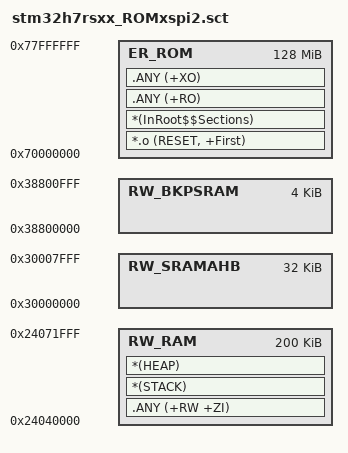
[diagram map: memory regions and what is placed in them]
; *************************************************************
; *** Scatter-Loading Description File generated by uVision ***
; *************************************************************

LOAD_FLASH 0x70000000 0x10000000  {    ; load region size_region
  ER_ROM 0x70000000 0x08000000  {  ; load address = execution address
   *.o (RESET, +First)
   *(InRoot$$Sections)
   .ANY (+RO)
   .ANY (+XO)
  }

  RW_SRAMAHB 0x30000000 0x8000  {
  }

  RW_BKPSRAM 0x38800000 0x1000  {
  }

  RW_RAM 0x24040000 0x32000  {
   .ANY (+RW +ZI)
   *(STACK)
   *(HEAP)
  }
}
